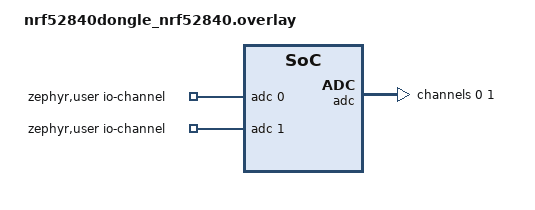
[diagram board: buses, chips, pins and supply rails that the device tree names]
/ {
    zephyr,user {
        io-channels = <&adc 0>, <&adc 1>;
    };
};

&adc {
    status = "okay";
    #address-cells = <1>;
    #size-cells = <0>;

    channel@0 {
        reg = <0>;
        zephyr,gain = "ADC_GAIN_1_5";
        zephyr,reference = "ADC_REF_INTERNAL";
        zephyr,acquisition-time = <ADC_ACQ_TIME_DEFAULT>;
        zephyr,resolution = <12>;
        zephyr,input-positive = <NRF_SAADC_AIN0>; /* P0.02 */
    };

    channel@1 {
        reg = <1>;
        zephyr,gain = "ADC_GAIN_1_5";
        zephyr,reference = "ADC_REF_INTERNAL";
        zephyr,acquisition-time = <ADC_ACQ_TIME_DEFAULT>;
        zephyr,resolution = <12>;
        zephyr,input-positive = <NRF_SAADC_AIN1>; /* P0.03 */
    };
};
